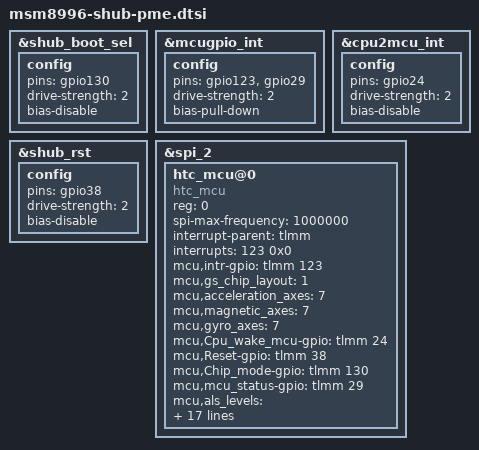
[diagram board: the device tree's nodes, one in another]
&shub_boot_sel {
	config {
		pins = "gpio130";
		drive-strength = <2>;
		bias-disable;
	};
};

&mcugpio_int {
	config {
		pins = "gpio123", "gpio29";
		drive-strength = <2>;
		bias-pull-down;
	};
};

&cpu2mcu_int {
	config {
		pins = "gpio24";
		drive-strength = <2>;
		bias-disable;
	};
};

&shub_rst {
	config {
		pins = "gpio38";
		drive-strength = <2>;
		bias-disable;
	};
};

&spi_2 {
	htc_mcu@0 {
			compatible = "htc_mcu";
			reg = <0>;
			spi-max-frequency = <1000000>;
			interrupt-parent = <&tlmm>;
			interrupts = <123 0x0>;
			mcu,intr-gpio  = <&tlmm 123 0>;
			mcu,gs_chip_layout = <1>;
			mcu,acceleration_axes = <7>;
			mcu,magnetic_axes = <7>;
			mcu,gyro_axes = <7>;
			mcu,Cpu_wake_mcu-gpio = <&tlmm 24 0>;
			mcu,Reset-gpio = <&tlmm 38 0>;
			mcu,Chip_mode-gpio = <&tlmm 130 0>;
			mcu,mcu_status-gpio = <&tlmm 29 0>;
			mcu,als_levels = <5 16 23 91 421 2832 5379 8194 11721 65535>;
			mcu,als_leveltolux = <0 4 10 16 75 150 1000 1500 2700 4070>;
			mcu,als_polling = <1>;
			mcu,als_lux_ratio_n = <85>;      /* Numerator */
			mcu,als_lux_ratio_d = <100>;     /* Denominator */
			mcu,als_goldl = <0xFA>;
			mcu,als_goldh = <0x03>;
			mcu,ps_thd_add = <0x28>;
			mcu,ps_thd_fixed = <0x15>;
			mcu,ps_info = <1>;
			pinctrl-names = "mcu_gpio_init";
			pinctrl-0 = <&shub_rst &mcugpio_int &shub_boot_sel &cpu2mcu_int>;
			touch_enable = <1>;
			vibrate_ms = <25>;
			V_SR_2V85-supply = <&pm8994_l19>;
			V_SRIO_1V8-supply = <&pm8994_lvs2>;
	};

/*	htc_mcu_flash@0 {
			compatible = "htc_mcu_flash";
			spi-max-frequency = <50000000>;
			reg = <0>;
	};

	htc_mcu_dload@0 {
			compatible = "htc_mcu_dload";
			spi-max-frequency = <50000000>;
			reg = <0>;
	};*/
};
